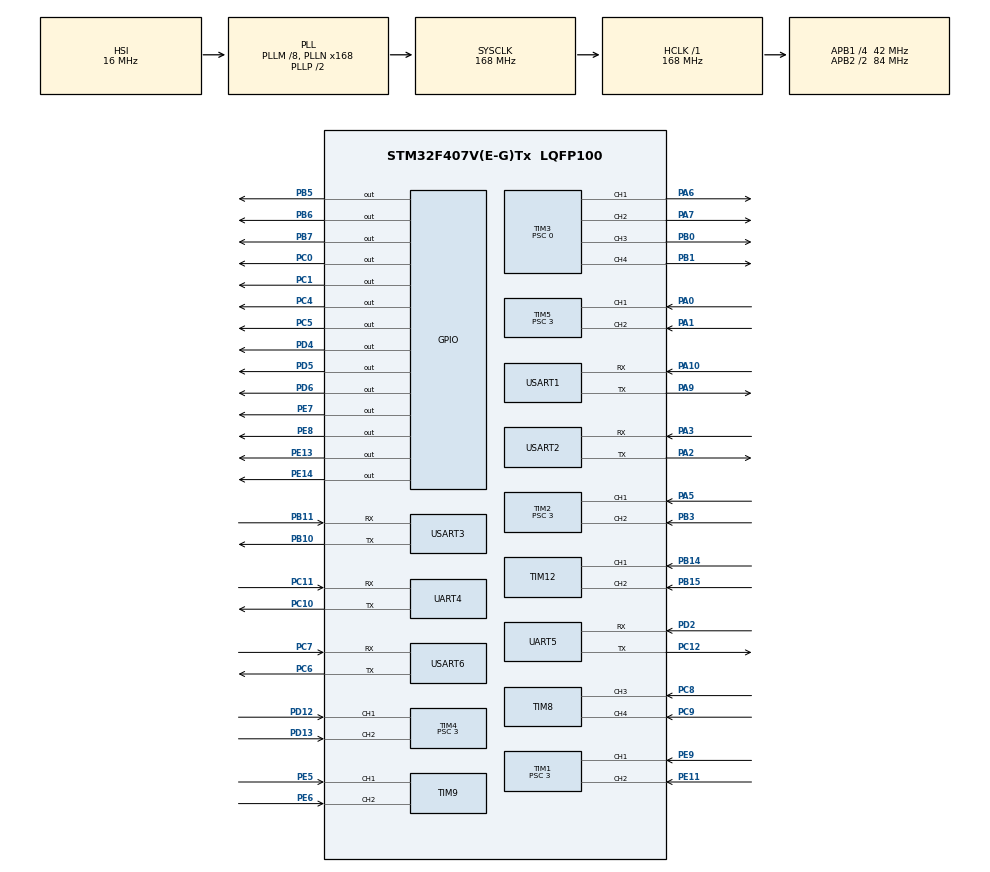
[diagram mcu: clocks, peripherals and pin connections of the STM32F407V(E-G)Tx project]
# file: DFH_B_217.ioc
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Dma.Request0=USART2_RX
Dma.Request1=USART2_TX
Dma.Request10=UART4_RX
Dma.Request11=UART4_TX
Dma.Request2=USART3_RX
Dma.Request3=USART3_TX
Dma.Request4=USART1_TX
Dma.Request5=USART1_RX
Dma.Request6=USART6_RX
Dma.Request7=USART6_TX
Dma.Request8=UART5_RX
Dma.Request9=UART5_TX
Dma.UART4_RX.10.Direction=DMA_PERIPH_TO_MEMORY
Dma.UART4_RX.10.FIFOMode=DMA_FIFOMODE_DISABLE
Dma.UART4_RX.10.Instance=DMA1_Stream2
Dma.UART4_RX.10.MemDataAlignment=DMA_MDATAALIGN_BYTE
Dma.UART4_RX.10.MemInc=DMA_MINC_ENABLE
Dma.UART4_RX.10.Mode=DMA_NORMAL
Dma.UART4_RX.10.PeriphDataAlignment=DMA_PDATAALIGN_BYTE
Dma.UART4_RX.10.PeriphInc=DMA_PINC_DISABLE
Dma.UART4_RX.10.Priority=DMA_PRIORITY_LOW
Dma.UART4_TX.11.Direction=DMA_MEMORY_TO_PERIPH
Dma.UART4_TX.11.FIFOMode=DMA_FIFOMODE_DISABLE
Dma.UART4_TX.11.Instance=DMA1_Stream4
Dma.UART4_TX.11.MemDataAlignment=DMA_MDATAALIGN_BYTE
Dma.UART4_TX.11.MemInc=DMA_MINC_ENABLE
Dma.UART4_TX.11.Mode=DMA_NORMAL
Dma.UART4_TX.11.PeriphDataAlignment=DMA_PDATAALIGN_BYTE
Dma.UART4_TX.11.PeriphInc=DMA_PINC_DISABLE
Dma.UART4_TX.11.Priority=DMA_PRIORITY_LOW
Dma.UART5_RX.8.Direction=DMA_PERIPH_TO_MEMORY
Dma.UART5_RX.8.FIFOMode=DMA_FIFOMODE_DISABLE
Dma.UART5_RX.8.Instance=DMA1_Stream0
Dma.UART5_RX.8.MemDataAlignment=DMA_MDATAALIGN_BYTE
Dma.UART5_RX.8.MemInc=DMA_MINC_ENABLE
Dma.UART5_RX.8.Mode=DMA_NORMAL
Dma.UART5_RX.8.PeriphDataAlignment=DMA_PDATAALIGN_BYTE
Dma.UART5_RX.8.PeriphInc=DMA_PINC_DISABLE
Dma.UART5_RX.8.Priority=DMA_PRIORITY_LOW
Dma.UART5_TX.9.Direction=DMA_MEMORY_TO_PERIPH
Dma.UART5_TX.9.FIFOMode=DMA_FIFOMODE_DISABLE
Dma.UART5_TX.9.Instance=DMA1_Stream7
Dma.UART5_TX.9.MemDataAlignment=DMA_MDATAALIGN_BYTE
Dma.UART5_TX.9.MemInc=DMA_MINC_ENABLE
Dma.UART5_TX.9.Mode=DMA_NORMAL
Dma.UART5_TX.9.PeriphDataAlignment=DMA_PDATAALIGN_BYTE
Dma.UART5_TX.9.PeriphInc=DMA_PINC_DISABLE
Dma.UART5_TX.9.Priority=DMA_PRIORITY_LOW
Dma.USART1_RX.5.Direction=DMA_PERIPH_TO_MEMORY
Dma.USART1_RX.5.FIFOMode=DMA_FIFOMODE_DISABLE
Dma.USART1_RX.5.Instance=DMA2_Stream2
Dma.USART1_RX.5.MemDataAlignment=DMA_MDATAALIGN_BYTE
Dma.USART1_RX.5.MemInc=DMA_MINC_ENABLE
Dma.USART1_RX.5.Mode=DMA_CIRCULAR
Dma.USART1_RX.5.PeriphDataAlignment=DMA_PDATAALIGN_BYTE
Dma.USART1_RX.5.PeriphInc=DMA_PINC_DISABLE
Dma.USART1_RX.5.Priority=DMA_PRIORITY_LOW
Dma.USART1_TX.4.Direction=DMA_MEMORY_TO_PERIPH
Dma.USART1_TX.4.FIFOMode=DMA_FIFOMODE_DISABLE
Dma.USART1_TX.4.Instance=DMA2_Stream7
Dma.USART1_TX.4.MemDataAlignment=DMA_MDATAALIGN_BYTE
Dma.USART1_TX.4.MemInc=DMA_MINC_ENABLE
Dma.USART1_TX.4.Mode=DMA_CIRCULAR
Dma.USART1_TX.4.PeriphDataAlignment=DMA_PDATAALIGN_BYTE
Dma.USART1_TX.4.PeriphInc=DMA_PINC_DISABLE
Dma.USART1_TX.4.Priority=DMA_PRIORITY_LOW
Dma.USART2_RX.0.Direction=DMA_PERIPH_TO_MEMORY
Dma.USART2_RX.0.FIFOMode=DMA_FIFOMODE_DISABLE
Dma.USART2_RX.0.Instance=DMA1_Stream5
Dma.USART2_RX.0.MemDataAlignment=DMA_MDATAALIGN_BYTE
Dma.USART2_RX.0.MemInc=DMA_MINC_ENABLE
Dma.USART2_RX.0.Mode=DMA_CIRCULAR
Dma.USART2_RX.0.PeriphDataAlignment=DMA_PDATAALIGN_BYTE
Dma.USART2_RX.0.PeriphInc=DMA_PINC_DISABLE
Dma.USART2_RX.0.Priority=DMA_PRIORITY_LOW
Dma.USART2_TX.1.Direction=DMA_MEMORY_TO_PERIPH
Dma.USART2_TX.1.FIFOMode=DMA_FIFOMODE_DISABLE
Dma.USART2_TX.1.Instance=DMA1_Stream6
Dma.USART2_TX.1.MemDataAlignment=DMA_MDATAALIGN_BYTE
Dma.USART2_TX.1.MemInc=DMA_MINC_ENABLE
Dma.USART2_TX.1.Mode=DMA_CIRCULAR
Dma.USART2_TX.1.PeriphDataAlignment=DMA_PDATAALIGN_BYTE
Dma.USART2_TX.1.PeriphInc=DMA_PINC_DISABLE
Dma.USART2_TX.1.Priority=DMA_PRIORITY_LOW
Dma.USART3_RX.2.Direction=DMA_PERIPH_TO_MEMORY
Dma.USART3_RX.2.FIFOMode=DMA_FIFOMODE_DISABLE
Dma.USART3_RX.2.Instance=DMA1_Stream1
Dma.USART3_RX.2.MemDataAlignment=DMA_MDATAALIGN_BYTE
Dma.USART3_RX.2.MemInc=DMA_MINC_ENABLE
Dma.USART3_RX.2.Mode=DMA_CIRCULAR
Dma.USART3_RX.2.PeriphDataAlignment=DMA_PDATAALIGN_BYTE
Dma.USART3_RX.2.PeriphInc=DMA_PINC_DISABLE
Dma.USART3_RX.2.Priority=DMA_PRIORITY_LOW
Dma.USART3_TX.3.Direction=DMA_MEMORY_TO_PERIPH
Dma.USART3_TX.3.FIFOMode=DMA_FIFOMODE_DISABLE
Dma.USART3_TX.3.Instance=DMA1_Stream3
Dma.USART3_TX.3.MemDataAlignment=DMA_MDATAALIGN_BYTE
Dma.USART3_TX.3.MemInc=DMA_MINC_ENABLE
Dma.USART3_TX.3.Mode=DMA_CIRCULAR
Dma.USART3_TX.3.PeriphDataAlignment=DMA_PDATAALIGN_BYTE
Dma.USART3_TX.3.PeriphInc=DMA_PINC_DISABLE
Dma.USART3_TX.3.Priority=DMA_PRIORITY_LOW
Dma.USART6_RX.6.Direction=DMA_PERIPH_TO_MEMORY
Dma.USART6_RX.6.FIFOMode=DMA_FIFOMODE_DISABLE
Dma.USART6_RX.6.Instance=DMA2_Stream1
Dma.USART6_RX.6.MemDataAlignment=DMA_MDATAALIGN_BYTE
Dma.USART6_RX.6.MemInc=DMA_MINC_ENABLE
Dma.USART6_RX.6.Mode=DMA_CIRCULAR
Dma.USART6_RX.6.PeriphDataAlignment=DMA_PDATAALIGN_BYTE
Dma.USART6_RX.6.PeriphInc=DMA_PINC_DISABLE
Dma.USART6_RX.6.Priority=DMA_PRIORITY_LOW
Dma.USART6_TX.7.Direction=DMA_MEMORY_TO_PERIPH
Dma.USART6_TX.7.FIFOMode=DMA_FIFOMODE_DISABLE
Dma.USART6_TX.7.Instance=DMA2_Stream6
Dma.USART6_TX.7.MemDataAlignment=DMA_MDATAALIGN_BYTE
Dma.USART6_TX.7.MemInc=DMA_MINC_ENABLE
Dma.USART6_TX.7.Mode=DMA_CIRCULAR
Dma.USART6_TX.7.PeriphDataAlignment=DMA_PDATAALIGN_BYTE
Dma.USART6_TX.7.PeriphInc=DMA_PINC_DISABLE
Dma.USART6_TX.7.Priority=DMA_PRIORITY_LOW
FREERTOS.INCLUDE_vTaskDelayUntil=1
FREERTOS.Tasks01=defaultTask,0,128,StartDefaultTask,Default,NULL,Dynamic,NULL,NULL;CHASSIS,1,512,Chassis_User,Default,NULL,Dynamic,NULL,NULL
FREERTOS.Timers01=ULTRASONIC,CSB_UserCallback,osTimerPeriodic,Default,NULL,Dynamic,NULL;PID,PID_UserCallback,osTimerPeriodic,Default,NULL,Dynamic,NULL
FREERTOS.configUSE_TIMERS=1
Mcu.Family=STM32F4
Mcu.Name=STM32F407V(E-G)Tx
Mcu.Package=LQFP100
NVIC.DMA1_Stream0_IRQn=true\:5\:0\:false\:false\:true\:true\:false\:true
NVIC.DMA1_Stream1_IRQn=true\:5\:0\:false\:false\:true\:true\:false\:true
NVIC.DMA1_Stream2_IRQn=true\:5\:0\:false\:false\:true\:true\:false\:true
NVIC.DMA1_Stream3_IRQn=true\:5\:0\:false\:false\:true\:true\:false\:true
NVIC.DMA1_Stream4_IRQn=true\:5\:0\:false\:false\:true\:true\:false\:true
NVIC.DMA1_Stream5_IRQn=true\:5\:0\:false\:false\:true\:true\:false\:true
NVIC.DMA1_Stream6_IRQn=true\:5\:0\:false\:false\:true\:true\:false\:true
NVIC.DMA1_Stream7_IRQn=true\:5\:0\:false\:false\:true\:true\:false\:true
NVIC.DMA2_Stream1_IRQn=true\:5\:0\:false\:false\:true\:true\:false\:true
NVIC.DMA2_Stream2_IRQn=true\:5\:0\:false\:false\:true\:true\:false\:true
NVIC.DMA2_Stream6_IRQn=true\:5\:0\:false\:false\:true\:true\:false\:true
NVIC.DMA2_Stream7_IRQn=true\:5\:0\:false\:false\:true\:true\:false\:true
NVIC.PriorityGroup=NVIC_PRIORITYGROUP_4
NVIC.TIM1_BRK_TIM9_IRQn=true\:5\:0\:false\:false\:true\:true\:true\:true
NVIC.TIM1_CC_IRQn=true\:5\:0\:false\:false\:true\:true\:true\:true
NVIC.TIM1_TRG_COM_TIM11_IRQn=true\:5\:0\:false\:false\:true\:true\:true\:true
NVIC.TIM1_UP_TIM10_IRQn=true\:5\:0\:false\:false\:true\:true\:true\:true
NVIC.UART4_IRQn=true\:5\:0\:false\:false\:true\:true\:true\:true
NVIC.UART5_IRQn=true\:5\:0\:false\:false\:true\:true\:true\:true
NVIC.USART1_IRQn=true\:5\:0\:false\:false\:true\:true\:true\:true
NVIC.USART2_IRQn=true\:5\:0\:false\:false\:true\:true\:true\:true
NVIC.USART3_IRQn=true\:5\:0\:false\:false\:true\:true\:true\:true
NVIC.USART6_IRQn=true\:5\:0\:false\:false\:true\:true\:true\:true
PA0-WKUP.Signal=S_TIM5_CH1
PA1.Signal=S_TIM5_CH2
PA10.Mode=Asynchronous
PA10.Signal=USART1_RX
PA2.Mode=Asynchronous
PA2.Signal=USART2_TX
PA3.Mode=Asynchronous
PA3.Signal=USART2_RX
PA5.Signal=S_TIM2_CH1_ETR
PA6.Signal=S_TIM3_CH1
PA7.Signal=S_TIM3_CH2
PA9.Mode=Asynchronous
PA9.Signal=USART1_TX
PB0.Signal=S_TIM3_CH3
PB1.Signal=S_TIM3_CH4
PB10.Mode=Asynchronous
PB10.Signal=USART3_TX
PB11.Mode=Asynchronous
PB11.Signal=USART3_RX
PB14.Signal=S_TIM12_CH1
PB15.Signal=S_TIM12_CH2
PB3.Signal=S_TIM2_CH2
PB5.GPIO_ModeDefaultOutputPP=GPIO_MODE_OUTPUT_PP
PB5.GPIO_PuPd=GPIO_PULLDOWN
PB5.GPIO_Speed=GPIO_SPEED_FREQ_VERY_HIGH
PB5.Signal=GPIO_Output
PB6.GPIO_PuPd=GPIO_PULLDOWN
PB6.GPIO_Speed=GPIO_SPEED_FREQ_VERY_HIGH
PB6.Signal=GPIO_Output
PB7.GPIO_PuPd=GPIO_PULLDOWN
PB7.GPIO_Speed=GPIO_SPEED_FREQ_VERY_HIGH
PB7.Signal=GPIO_Output
PC0.GPIO_ModeDefaultOutputPP=GPIO_MODE_OUTPUT_OD
PC0.GPIO_PuPd=GPIO_PULLUP
PC0.GPIO_Speed=GPIO_SPEED_FREQ_VERY_HIGH
PC0.Signal=GPIO_Output
PC1.GPIO_ModeDefaultOutputPP=GPIO_MODE_OUTPUT_OD
PC1.GPIO_PuPd=GPIO_PULLUP
PC1.GPIO_Speed=GPIO_SPEED_FREQ_VERY_HIGH
PC1.Signal=GPIO_Output
PC10.Mode=Asynchronous
PC10.Signal=UART4_TX
PC11.Mode=Asynchronous
PC11.Signal=UART4_RX
PC12.Mode=Asynchronous
PC12.Signal=UART5_TX
PC4.GPIO_ModeDefaultOutputPP=GPIO_MODE_OUTPUT_OD
PC4.GPIO_PuPd=GPIO_PULLUP
PC4.GPIO_Speed=GPIO_SPEED_FREQ_VERY_HIGH
PC4.Signal=GPIO_Output
PC5.GPIO_ModeDefaultOutputPP=GPIO_MODE_OUTPUT_OD
PC5.GPIO_PuPd=GPIO_PULLUP
PC5.GPIO_Speed=GPIO_SPEED_FREQ_VERY_HIGH
PC5.Signal=GPIO_Output
PC6.Mode=Asynchronous
PC6.Signal=USART6_TX
PC7.Mode=Asynchronous
PC7.Signal=USART6_RX
PC8.Signal=S_TIM8_CH3
PC9.Signal=S_TIM8_CH4
PD12.Signal=S_TIM4_CH1
PD13.Signal=S_TIM4_CH2
PD2.Mode=Asynchronous
PD2.Signal=UART5_RX
PD4.GPIO_PuPd=GPIO_PULLDOWN
PD4.GPIO_Speed=GPIO_SPEED_FREQ_VERY_HIGH
PD4.Signal=GPIO_Output
PD5.GPIO_PuPd=GPIO_PULLDOWN
PD5.GPIO_Speed=GPIO_SPEED_FREQ_VERY_HIGH
PD5.Signal=GPIO_Output
PD6.GPIO_PuPd=GPIO_PULLDOWN
PD6.GPIO_Speed=GPIO_SPEED_FREQ_VERY_HIGH
PD6.Signal=GPIO_Output
PE11.Signal=S_TIM1_CH2
PE13.GPIO_ModeDefaultOutputPP=GPIO_MODE_OUTPUT_OD
PE13.GPIO_PuPd=GPIO_PULLUP
PE13.GPIO_Speed=GPIO_SPEED_FREQ_VERY_HIGH
PE13.Signal=GPIO_Output
PE14.GPIO_ModeDefaultOutputPP=GPIO_MODE_OUTPUT_OD
PE14.GPIO_PuPd=GPIO_PULLUP
PE14.GPIO_Speed=GPIO_SPEED_FREQ_VERY_HIGH
PE14.Signal=GPIO_Output
PE5.Signal=S_TIM9_CH1
PE6.Signal=S_TIM9_CH2
PE7.GPIO_ModeDefaultOutputPP=GPIO_MODE_OUTPUT_OD
PE7.GPIO_PuPd=GPIO_PULLUP
PE7.GPIO_Speed=GPIO_SPEED_FREQ_VERY_HIGH
PE7.Signal=GPIO_Output
PE8.GPIO_ModeDefaultOutputPP=GPIO_MODE_OUTPUT_OD
PE8.GPIO_PuPd=GPIO_PULLUP
PE8.GPIO_Speed=GPIO_SPEED_FREQ_VERY_HIGH
PE8.Signal=GPIO_Output
PE9.Signal=S_TIM1_CH1
PH0-OSC_IN.Mode=HSE-External-Oscillator
PH0-OSC_IN.Signal=RCC_OSC_IN
PH1-OSC_OUT.Mode=HSE-External-Oscillator
PH1-OSC_OUT.Signal=RCC_OSC_OUT
ProjectManager.HeapSize=0x200
ProjectManager.StackSize=0x400
ProjectManager.TargetToolchain=MDK-ARM V5
RCC.48MHZClocksFreq_Value=84000000
RCC.AHBFreq_Value=168000000
RCC.APB1CLKDivider=RCC_HCLK_DIV4
RCC.APB1Freq_Value=42000000
RCC.APB1TimFreq_Value=84000000
RCC.APB2CLKDivider=RCC_HCLK_DIV2
RCC.APB2Freq_Value=84000000
RCC.APB2TimFreq_Value=168000000
RCC.CortexFreq_Value=168000000
RCC.HCLKFreq_Value=168000000
RCC.HSE_VALUE=25000000
RCC.HSI_VALUE=16000000
RCC.LSE_VALUE=32768
RCC.PLLM=8
RCC.PLLN=168
RCC.SYSCLKFreq_VALUE=168000000
RCC.SYSCLKSource=RCC_SYSCLKSOURCE_PLLCLK
RCC.VCOOutputFreq_Value=336000000
SH.S_TIM12_CH1.0=TIM12_CH1,Input_Capture1_from_TI1
SH.S_TIM12_CH2.0=TIM12_CH2,Input_Capture2_from_TI2
SH.S_TIM1_CH1.0=TIM1_CH1,Encoder_Interface
SH.S_TIM1_CH2.0=TIM1_CH2,Encoder_Interface
SH.S_TIM2_CH1_ETR.0=TIM2_CH1,Encoder_Interface
SH.S_TIM2_CH2.0=TIM2_CH2,Encoder_Interface
SH.S_TIM3_CH1.0=TIM3_CH1,PWM Generation1 CH1
SH.S_TIM3_CH2.0=TIM3_CH2,PWM Generation2 CH2
SH.S_TIM3_CH3.0=TIM3_CH3,PWM Generation3 CH3
SH.S_TIM3_CH4.0=TIM3_CH4,PWM Generation4 CH4
SH.S_TIM4_CH1.0=TIM4_CH1,Encoder_Interface
SH.S_TIM4_CH2.0=TIM4_CH2,Encoder_Interface
SH.S_TIM5_CH1.0=TIM5_CH1,Encoder_Interface
SH.S_TIM5_CH2.0=TIM5_CH2,Encoder_Interface
SH.S_TIM8_CH3.0=TIM8_CH3,Input_Capture3_from_TI3
SH.S_TIM8_CH4.0=TIM8_CH4,Input_Capture4_from_TI4
SH.S_TIM9_CH1.0=TIM9_CH1,Input_Capture1_from_TI1
SH.S_TIM9_CH2.0=TIM9_CH2,Input_Capture2_from_TI2
TIM1.EncoderMode=TIM_ENCODERMODE_TI12
TIM1.Period=65535
TIM1.Prescaler=3  
TIM12.Channel-Input_Capture1_from_TI1=TIM_CHANNEL_1
TIM12.Channel-Input_Capture2_from_TI2=TIM_CHANNEL_2
TIM2.EncoderMode=TIM_ENCODERMODE_TI12
TIM2.Period=65535
TIM2.Prescaler=3
TIM3.Channel-PWM\ Generation1\ CH1=TIM_CHANNEL_1
TIM3.Channel-PWM\ Generation2\ CH2=TIM_CHANNEL_2
TIM3.Channel-PWM\ Generation3\ CH3=TIM_CHANNEL_3
TIM3.Channel-PWM\ Generation4\ CH4=TIM_CHANNEL_4
TIM3.Prescaler=0
TIM4.EncoderMode=TIM_ENCODERMODE_TI12
TIM4.Period=65535
TIM4.Prescaler=3
TIM5.EncoderMode=TIM_ENCODERMODE_TI12
TIM5.Period=65535
TIM5.Prescaler=3
TIM8.Channel-Input_Capture3_from_TI3=TIM_CHANNEL_3
TIM8.Channel-Input_Capture4_from_TI4=TIM_CHANNEL_4
TIM9.Channel-Input_Capture1_from_TI1=TIM_CHANNEL_1
TIM9.Channel-Input_Capture2_from_TI2=TIM_CHANNEL_2
UART4.VirtualMode=Asynchronous
UART5.VirtualMode=Asynchronous
USART1.VirtualMode=VM_ASYNC
USART2.VirtualMode=VM_ASYNC
USART3.VirtualMode=VM_ASYNC
USART6.VirtualMode=VM_ASYNC
VP_FREERTOS_VS_CMSIS_V1.Mode=CMSIS_V1
board=custom

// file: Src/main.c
/* USER CODE BEGIN Header */
/**
  ******************************************************************************
  * @file           : main.c
  * @brief          : Main program body
  ******************************************************************************
  * @attention
  *
  * <h2><center>&copy; Copyright (c) 2019 STMicroelectronics.
  * All rights reserved.</center></h2>
  *
  * This software component is licensed by ST under BSD 3-Clause license,
  * the "License"; You may not use this file except in compliance with the
  * License. You may obtain a copy of the License at:
  *                        opensource.org/licenses/BSD-3-Clause
  *
  ******************************************************************************
  */
/* USER CODE END Header */

#include "main.h"
#include "cmsis_os.h"
#include "dma.h"
#include "tim.h"
#include "usart.h"
#include "gpio.h"

void SystemClock_Config(void);
void MX_FREERTOS_Init(void);

/* USER CODE BEGIN 0 */
//uint8_t receive_buff[DMA_buff];
/* USER CODE END 0 */

int main(void)
{

  /* MCU Configuration--------------------------------------------------------*/

  /* Reset of all peripherals, Initializes the Flash interface and the Systick. */
  HAL_Init();

  /* Configure the system clock */
  SystemClock_Config();

  /* Initialize all configured peripherals */
  MX_GPIO_Init();
  MX_DMA_Init();
  MX_TIM1_Init();
  MX_TIM2_Init();
  MX_TIM3_Init();
  MX_TIM4_Init();
  MX_TIM5_Init();
  MX_TIM8_Init();
  MX_TIM9_Init();
  MX_TIM12_Init();
  MX_UART4_Init();
  MX_UART5_Init();
  MX_USART1_UART_Init();
  MX_USART2_UART_Init();
  MX_USART3_UART_Init();
  MX_USART6_UART_Init();
  /* USER CODE BEGIN 2 */
	USER_UART_IT_ENABLE();
  /* USER CODE END 2 */

  /* Call init function for freertos objects (in freertos.c) */
  MX_FREERTOS_Init();

  /* Start scheduler */
  osKernelStart();

  /* We should never get here as control is now taken by the scheduler */

  /* Infinite loop */
  while (1)
  {

  }
}

void SystemClock_Config(void)
{
  RCC_OscInitTypeDef RCC_OscInitStruct = {0};
  RCC_ClkInitTypeDef RCC_ClkInitStruct = {0};

  /** Configure the main internal regulator output voltage
  */
  __HAL_RCC_PWR_CLK_ENABLE();
  __HAL_PWR_VOLTAGESCALING_CONFIG(PWR_REGULATOR_VOLTAGE_SCALE1);
  /** Initializes the CPU, AHB and APB busses clocks
  */
  RCC_OscInitStruct.OscillatorType = RCC_OSCILLATORTYPE_HSI;
  RCC_OscInitStruct.HSIState = RCC_HSI_ON;
  RCC_OscInitStruct.HSICalibrationValue = RCC_HSICALIBRATION_DEFAULT;
  RCC_OscInitStruct.PLL.PLLState = RCC_PLL_ON;
  RCC_OscInitStruct.PLL.PLLSource = RCC_PLLSOURCE_HSI;
  RCC_OscInitStruct.PLL.PLLM = 8;
  RCC_OscInitStruct.PLL.PLLN = 168;
  RCC_OscInitStruct.PLL.PLLP = RCC_PLLP_DIV2;
  RCC_OscInitStruct.PLL.PLLQ = 4;
  if (HAL_RCC_OscConfig(&RCC_OscInitStruct) != HAL_OK)
  {
    Error_Handler();
  }
  /** Initializes the CPU, AHB and APB busses clocks
  */
  RCC_ClkInitStruct.ClockType = RCC_CLOCKTYPE_HCLK|RCC_CLOCKTYPE_SYSCLK
                              |RCC_CLOCKTYPE_PCLK1|RCC_CLOCKTYPE_PCLK2;
  RCC_ClkInitStruct.SYSCLKSource = RCC_SYSCLKSOURCE_PLLCLK;
  RCC_ClkInitStruct.AHBCLKDivider = RCC_SYSCLK_DIV1;
  RCC_ClkInitStruct.APB1CLKDivider = RCC_HCLK_DIV4;
  RCC_ClkInitStruct.APB2CLKDivider = RCC_HCLK_DIV2;

  if (HAL_RCC_ClockConfig(&RCC_ClkInitStruct, FLASH_LATENCY_5) != HAL_OK)
  {
    Error_Handler();
  }
}

void Error_Handler(void)
{
}

/************************ (C) COPYRIGHT STMicroelectronics *****END OF FILE****/
